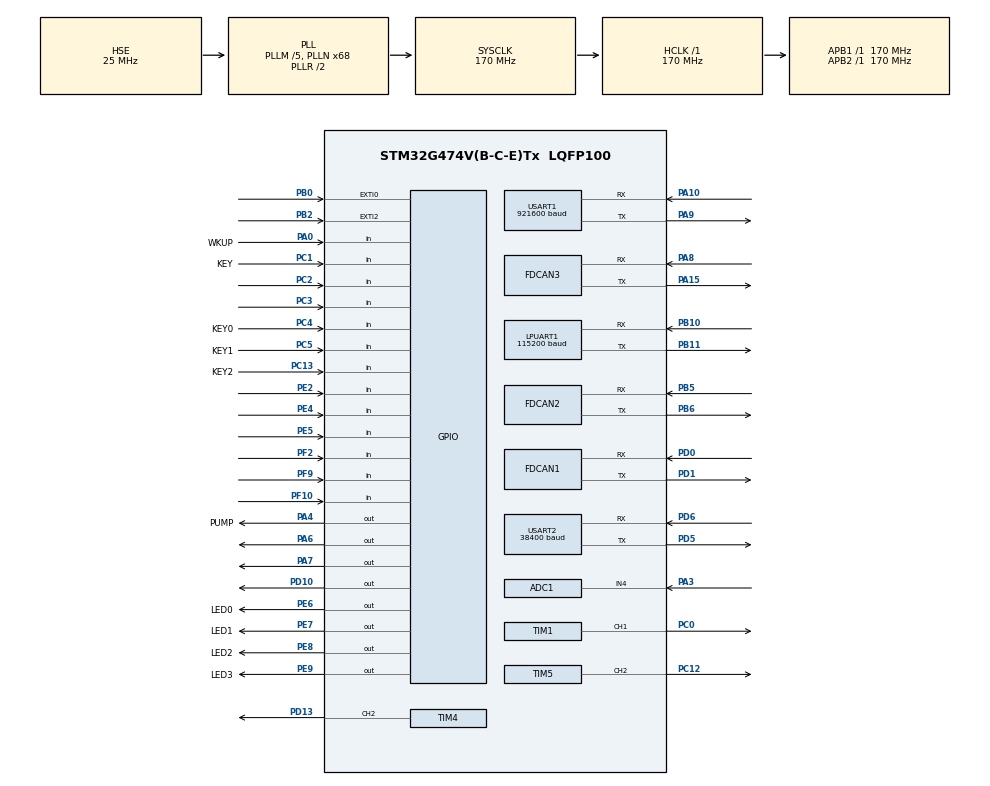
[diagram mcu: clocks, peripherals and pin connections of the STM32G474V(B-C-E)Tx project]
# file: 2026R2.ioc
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ADC1.Channel-1\#ChannelRegularConversion=ADC_CHANNEL_4
ADC1.ContinuousConvMode=ENABLE
ADC1.NbrOfConversionFlag=1
ADC1.OffsetNumber-1\#ChannelRegularConversion=ADC_OFFSET_NONE
ADC1.Overrun=ADC_OVR_DATA_OVERWRITTEN
ADC1.OversamplingMode=ENABLE
ADC1.Rank-1\#ChannelRegularConversion=1
ADC1.Ratio=ADC_OVERSAMPLING_RATIO_16
ADC1.RightBitShift=ADC_RIGHTBITSHIFT_4
ADC1.SamplingTime-1\#ChannelRegularConversion=ADC_SAMPLETIME_24CYCLES_5
ADC1.master=1
Dma.LPUART1_RX.2.Direction=DMA_PERIPH_TO_MEMORY
Dma.LPUART1_RX.2.EventEnable=DISABLE
Dma.LPUART1_RX.2.Instance=DMA1_Channel3
Dma.LPUART1_RX.2.MemDataAlignment=DMA_MDATAALIGN_BYTE
Dma.LPUART1_RX.2.MemInc=DMA_MINC_ENABLE
Dma.LPUART1_RX.2.Mode=DMA_NORMAL
Dma.LPUART1_RX.2.PeriphDataAlignment=DMA_PDATAALIGN_BYTE
Dma.LPUART1_RX.2.PeriphInc=DMA_PINC_DISABLE
Dma.LPUART1_RX.2.Polarity=HAL_DMAMUX_REQ_GEN_RISING
Dma.LPUART1_RX.2.Priority=DMA_PRIORITY_LOW
Dma.LPUART1_RX.2.RequestNumber=1
Dma.LPUART1_RX.2.SignalID=NONE
Dma.LPUART1_RX.2.SyncEnable=DISABLE
Dma.LPUART1_RX.2.SyncPolarity=HAL_DMAMUX_SYNC_NO_EVENT
Dma.LPUART1_RX.2.SyncRequestNumber=1
Dma.LPUART1_RX.2.SyncSignalID=NONE
Dma.LPUART1_TX.3.Direction=DMA_MEMORY_TO_PERIPH
Dma.LPUART1_TX.3.EventEnable=DISABLE
Dma.LPUART1_TX.3.Instance=DMA1_Channel4
Dma.LPUART1_TX.3.MemDataAlignment=DMA_MDATAALIGN_BYTE
Dma.LPUART1_TX.3.MemInc=DMA_MINC_ENABLE
Dma.LPUART1_TX.3.Mode=DMA_NORMAL
Dma.LPUART1_TX.3.PeriphDataAlignment=DMA_PDATAALIGN_BYTE
Dma.LPUART1_TX.3.PeriphInc=DMA_PINC_DISABLE
Dma.LPUART1_TX.3.Polarity=HAL_DMAMUX_REQ_GEN_RISING
Dma.LPUART1_TX.3.Priority=DMA_PRIORITY_LOW
Dma.LPUART1_TX.3.RequestNumber=1
Dma.LPUART1_TX.3.SignalID=NONE
Dma.LPUART1_TX.3.SyncEnable=DISABLE
Dma.LPUART1_TX.3.SyncPolarity=HAL_DMAMUX_SYNC_NO_EVENT
Dma.LPUART1_TX.3.SyncRequestNumber=1
Dma.LPUART1_TX.3.SyncSignalID=NONE
Dma.Request0=USART1_RX
Dma.Request1=USART1_TX
Dma.Request2=LPUART1_RX
Dma.Request3=LPUART1_TX
Dma.Request4=USART2_RX
Dma.Request5=USART2_TX
Dma.Request6=TIM5_CH2
Dma.Request7=TIM1_CH1
Dma.TIM1_CH1.7.Direction=DMA_MEMORY_TO_PERIPH
Dma.TIM1_CH1.7.EventEnable=DISABLE
Dma.TIM1_CH1.7.Instance=DMA2_Channel2
Dma.TIM1_CH1.7.MemDataAlignment=DMA_MDATAALIGN_HALFWORD
Dma.TIM1_CH1.7.MemInc=DMA_MINC_ENABLE
Dma.TIM1_CH1.7.Mode=DMA_NORMAL
Dma.TIM1_CH1.7.PeriphDataAlignment=DMA_PDATAALIGN_HALFWORD
Dma.TIM1_CH1.7.PeriphInc=DMA_PINC_DISABLE
Dma.TIM1_CH1.7.Polarity=HAL_DMAMUX_REQ_GEN_RISING
Dma.TIM1_CH1.7.Priority=DMA_PRIORITY_LOW
Dma.TIM1_CH1.7.RequestNumber=1
Dma.TIM1_CH1.7.SignalID=NONE
Dma.TIM1_CH1.7.SyncEnable=DISABLE
Dma.TIM1_CH1.7.SyncPolarity=HAL_DMAMUX_SYNC_NO_EVENT
Dma.TIM1_CH1.7.SyncRequestNumber=1
Dma.TIM1_CH1.7.SyncSignalID=NONE
Dma.TIM5_CH2.6.Direction=DMA_MEMORY_TO_PERIPH
Dma.TIM5_CH2.6.EventEnable=DISABLE
Dma.TIM5_CH2.6.Instance=DMA2_Channel1
Dma.TIM5_CH2.6.MemDataAlignment=DMA_MDATAALIGN_HALFWORD
Dma.TIM5_CH2.6.MemInc=DMA_MINC_ENABLE
Dma.TIM5_CH2.6.Mode=DMA_NORMAL
Dma.TIM5_CH2.6.PeriphDataAlignment=DMA_PDATAALIGN_HALFWORD
Dma.TIM5_CH2.6.PeriphInc=DMA_PINC_DISABLE
Dma.TIM5_CH2.6.Polarity=HAL_DMAMUX_REQ_GEN_RISING
Dma.TIM5_CH2.6.Priority=DMA_PRIORITY_MEDIUM
Dma.TIM5_CH2.6.RequestNumber=1
Dma.TIM5_CH2.6.SignalID=NONE
Dma.TIM5_CH2.6.SyncEnable=DISABLE
Dma.TIM5_CH2.6.SyncPolarity=HAL_DMAMUX_SYNC_NO_EVENT
Dma.TIM5_CH2.6.SyncRequestNumber=1
Dma.TIM5_CH2.6.SyncSignalID=NONE
Dma.USART1_RX.0.Direction=DMA_PERIPH_TO_MEMORY
Dma.USART1_RX.0.EventEnable=DISABLE
Dma.USART1_RX.0.Instance=DMA1_Channel1
Dma.USART1_RX.0.MemDataAlignment=DMA_MDATAALIGN_BYTE
Dma.USART1_RX.0.MemInc=DMA_MINC_ENABLE
Dma.USART1_RX.0.Mode=DMA_NORMAL
Dma.USART1_RX.0.PeriphDataAlignment=DMA_PDATAALIGN_BYTE
Dma.USART1_RX.0.PeriphInc=DMA_PINC_DISABLE
Dma.USART1_RX.0.Polarity=HAL_DMAMUX_REQ_GEN_RISING
Dma.USART1_RX.0.Priority=DMA_PRIORITY_MEDIUM
Dma.USART1_RX.0.RequestNumber=1
Dma.USART1_RX.0.SignalID=NONE
Dma.USART1_RX.0.SyncEnable=DISABLE
Dma.USART1_RX.0.SyncPolarity=HAL_DMAMUX_SYNC_NO_EVENT
Dma.USART1_RX.0.SyncRequestNumber=1
Dma.USART1_RX.0.SyncSignalID=NONE
Dma.USART1_TX.1.Direction=DMA_MEMORY_TO_PERIPH
Dma.USART1_TX.1.EventEnable=DISABLE
Dma.USART1_TX.1.Instance=DMA1_Channel2
Dma.USART1_TX.1.MemDataAlignment=DMA_MDATAALIGN_BYTE
Dma.USART1_TX.1.MemInc=DMA_MINC_ENABLE
Dma.USART1_TX.1.Mode=DMA_NORMAL
Dma.USART1_TX.1.PeriphDataAlignment=DMA_PDATAALIGN_BYTE
Dma.USART1_TX.1.PeriphInc=DMA_PINC_DISABLE
Dma.USART1_TX.1.Polarity=HAL_DMAMUX_REQ_GEN_RISING
Dma.USART1_TX.1.Priority=DMA_PRIORITY_MEDIUM
Dma.USART1_TX.1.RequestNumber=1
Dma.USART1_TX.1.SignalID=NONE
Dma.USART1_TX.1.SyncEnable=DISABLE
Dma.USART1_TX.1.SyncPolarity=HAL_DMAMUX_SYNC_NO_EVENT
Dma.USART1_TX.1.SyncRequestNumber=1
Dma.USART1_TX.1.SyncSignalID=NONE
Dma.USART2_RX.4.Direction=DMA_PERIPH_TO_MEMORY
Dma.USART2_RX.4.EventEnable=DISABLE
Dma.USART2_RX.4.Instance=DMA1_Channel7
Dma.USART2_RX.4.MemDataAlignment=DMA_MDATAALIGN_BYTE
Dma.USART2_RX.4.MemInc=DMA_MINC_ENABLE
Dma.USART2_RX.4.Mode=DMA_NORMAL
Dma.USART2_RX.4.PeriphDataAlignment=DMA_PDATAALIGN_BYTE
Dma.USART2_RX.4.PeriphInc=DMA_PINC_DISABLE
Dma.USART2_RX.4.Polarity=HAL_DMAMUX_REQ_GEN_RISING
Dma.USART2_RX.4.Priority=DMA_PRIORITY_LOW
Dma.USART2_RX.4.RequestNumber=1
Dma.USART2_RX.4.SignalID=NONE
Dma.USART2_RX.4.SyncEnable=DISABLE
Dma.USART2_RX.4.SyncPolarity=HAL_DMAMUX_SYNC_NO_EVENT
Dma.USART2_RX.4.SyncRequestNumber=1
Dma.USART2_RX.4.SyncSignalID=NONE
Dma.USART2_TX.5.Direction=DMA_MEMORY_TO_PERIPH
Dma.USART2_TX.5.EventEnable=DISABLE
Dma.USART2_TX.5.Instance=DMA1_Channel8
Dma.USART2_TX.5.MemDataAlignment=DMA_MDATAALIGN_BYTE
Dma.USART2_TX.5.MemInc=DMA_MINC_ENABLE
Dma.USART2_TX.5.Mode=DMA_NORMAL
Dma.USART2_TX.5.PeriphDataAlignment=DMA_PDATAALIGN_BYTE
Dma.USART2_TX.5.PeriphInc=DMA_PINC_DISABLE
Dma.USART2_TX.5.Polarity=HAL_DMAMUX_REQ_GEN_RISING
Dma.USART2_TX.5.Priority=DMA_PRIORITY_LOW
Dma.USART2_TX.5.RequestNumber=1
Dma.USART2_TX.5.SignalID=NONE
Dma.USART2_TX.5.SyncEnable=DISABLE
Dma.USART2_TX.5.SyncPolarity=HAL_DMAMUX_SYNC_NO_EVENT
Dma.USART2_TX.5.SyncRequestNumber=1
Dma.USART2_TX.5.SyncSignalID=NONE
FDCAN1.AutoRetransmission=ENABLE
FDCAN1.CalculateBaudRateNominal=999999
FDCAN1.CalculateTimeBitNominal=1000
FDCAN1.CalculateTimeQuantumNominal=58.82352941176471
FDCAN1.ClockDivider=FDCAN_CLOCK_DIV1
FDCAN1.ExtFiltersNbr=2
FDCAN1.NominalPrescaler=10
FDCAN1.NominalSyncJumpWidth=4
FDCAN1.NominalTimeSeg1=10
FDCAN1.NominalTimeSeg2=6
FDCAN1.ProtocolException=ENABLE
FDCAN1.StdFiltersNbr=2
FDCAN2.AutoRetransmission=ENABLE
FDCAN2.CalculateBaudRateNominal=999999
FDCAN2.CalculateTimeBitNominal=1000
FDCAN2.CalculateTimeQuantumNominal=58.82352941176471
FDCAN2.ExtFiltersNbr=2
FDCAN2.NominalPrescaler=10
FDCAN2.NominalSyncJumpWidth=4
FDCAN2.NominalTimeSeg1=10
FDCAN2.NominalTimeSeg2=6
FDCAN2.ProtocolException=ENABLE
FDCAN2.StdFiltersNbr=2
FDCAN3.AutoRetransmission=ENABLE
FDCAN3.CalculateBaudRateNominal=999999
FDCAN3.CalculateTimeBitNominal=1000
FDCAN3.CalculateTimeQuantumNominal=58.82352941176471
FDCAN3.ExtFiltersNbr=2
FDCAN3.NominalPrescaler=10
FDCAN3.NominalSyncJumpWidth=4
FDCAN3.NominalTimeSeg1=10
FDCAN3.NominalTimeSeg2=6
FDCAN3.ProtocolException=ENABLE
FDCAN3.StdFiltersNbr=2
LPUART1.BaudRate=115200
LPUART1.ClockPrescaler=UART_PRESCALER_DIV1
Mcu.Family=STM32G4
Mcu.Name=STM32G474V(B-C-E)Tx
Mcu.Package=LQFP100
NVIC.DMA1_Channel1_IRQn=true\:6\:0\:true\:false\:true\:false\:true\:true
NVIC.DMA1_Channel2_IRQn=true\:6\:0\:true\:false\:true\:false\:true\:true
NVIC.DMA1_Channel3_IRQn=true\:6\:0\:true\:false\:true\:false\:true\:true
NVIC.DMA1_Channel4_IRQn=true\:6\:0\:true\:false\:true\:false\:true\:true
NVIC.DMA1_Channel7_IRQn=true\:6\:0\:true\:false\:true\:false\:true\:true
NVIC.DMA1_Channel8_IRQn=true\:6\:0\:true\:false\:true\:false\:true\:true
NVIC.DMA2_Channel1_IRQn=true\:0\:0\:false\:false\:true\:false\:true\:true
NVIC.DMA2_Channel2_IRQn=true\:0\:0\:false\:false\:true\:false\:true\:true
NVIC.EXTI0_IRQn=true\:0\:0\:false\:false\:true\:true\:true\:true
NVIC.EXTI2_IRQn=true\:0\:0\:false\:false\:true\:true\:true\:true
NVIC.FDCAN1_IT0_IRQn=true\:5\:0\:true\:false\:true\:true\:true\:true
NVIC.FDCAN1_IT1_IRQn=true\:5\:0\:true\:false\:true\:true\:true\:true
NVIC.FDCAN2_IT0_IRQn=true\:5\:0\:true\:false\:true\:true\:true\:true
NVIC.FDCAN2_IT1_IRQn=true\:5\:0\:true\:false\:true\:true\:true\:true
NVIC.FDCAN3_IT0_IRQn=true\:5\:0\:true\:false\:true\:true\:true\:true
NVIC.FDCAN3_IT1_IRQn=true\:5\:0\:true\:false\:true\:true\:true\:true
NVIC.LPUART1_IRQn=true\:6\:0\:true\:false\:true\:true\:true\:true
NVIC.PriorityGroup=NVIC_PRIORITYGROUP_4
NVIC.USART1_IRQn=true\:6\:0\:true\:false\:true\:true\:true\:true
NVIC.USART2_IRQn=true\:6\:0\:true\:false\:true\:true\:true\:true
PA0.GPIO_Label=WKUP
PA0.GPIO_PuPd=GPIO_PULLDOWN
PA0.Signal=GPIO_Input
PA10.GPIO_PuPd=GPIO_PULLUP
PA10.GPIO_Speed=GPIO_SPEED_FREQ_HIGH
PA10.Mode=Asynchronous
PA10.Signal=USART1_RX
PA13.Mode=Trace_Asynchronous_SW
PA13.Signal=SYS_JTMS-SWDIO
PA14.Mode=Trace_Asynchronous_SW
PA14.Signal=SYS_JTCK-SWCLK
PA15.Mode=FDCAN_Activate
PA15.Signal=FDCAN3_TX
PA3.GPIO_Pd=GPIO_NOPULL
PA3.Mode=IN4-Single-Ended
PA3.Signal=ADC1_IN4
PA4.GPIO_Label=PUMP
PA4.Signal=GPIO_Output
PA6.GPIO_PuPd=GPIO_PULLDOWN
PA6.Signal=GPIO_Output
PA7.GPIO_PuPd=GPIO_PULLDOWN
PA7.Signal=GPIO_Output
PA8.Mode=FDCAN_Activate
PA8.Signal=FDCAN3_RX
PA9.GPIO_PuPd=GPIO_PULLUP
PA9.GPIO_Speed=GPIO_SPEED_FREQ_HIGH
PA9.Mode=Asynchronous
PA9.Signal=USART1_TX
PB0.GPIO_ModeDefaultEXTI=GPIO_MODE_IT_FALLING
PB0.GPIO_PuPd=GPIO_PULLUP
PB0.Signal=GPXTI0
PB10.GPIO_PuPd=GPIO_PULLUP
PB10.GPIO_Speed=GPIO_SPEED_FREQ_HIGH
PB10.Mode=Asynchronous
PB10.Signal=LPUART1_RX
PB11.GPIO_PuPd=GPIO_PULLUP
PB11.GPIO_Speed=GPIO_SPEED_FREQ_HIGH
PB11.Mode=Asynchronous
PB11.Signal=LPUART1_TX
PB2.GPIO_ModeDefaultEXTI=GPIO_MODE_IT_FALLING
PB2.GPIO_PuPd=GPIO_PULLUP
PB2.Signal=GPXTI2
PB3.Mode=Trace_Asynchronous_SW
PB3.Signal=SYS_JTDO-SWO
PB5.Mode=FDCAN_Activate
PB5.Signal=FDCAN2_RX
PB6.Mode=FDCAN_Activate
PB6.Signal=FDCAN2_TX
PC0.Signal=S_TIM1_CH1
PC1.GPIO_Label=KEY
PC1.GPIO_PuPd=GPIO_PULLUP
PC1.Signal=GPIO_Input
PC12.Signal=S_TIM5_CH2
PC13.GPIO_Label=KEY2
PC13.GPIO_PuPd=GPIO_PULLUP
PC13.Signal=GPIO_Input
PC14-OSC32_IN.Mode=LSE-External-Oscillator
PC14-OSC32_IN.Signal=RCC_OSC32_IN
PC15-OSC32_OUT.Mode=LSE-External-Oscillator
PC15-OSC32_OUT.Signal=RCC_OSC32_OUT
PC2.GPIO_PuPd=GPIO_PULLUP
PC2.Signal=GPIO_Input
PC3.GPIO_PuPd=GPIO_PULLUP
PC3.Signal=GPIO_Input
PC4.GPIO_Label=KEY0
PC4.GPIO_PuPd=GPIO_PULLUP
PC4.Signal=GPIO_Input
PC5.GPIO_Label=KEY1
PC5.GPIO_PuPd=GPIO_PULLUP
PC5.Signal=GPIO_Input
PD0.Mode=FDCAN_Activate
PD0.Signal=FDCAN1_RX
PD1.Mode=FDCAN_Activate
PD1.Signal=FDCAN1_TX
PD10.Signal=GPIO_Output
PD13.Signal=S_TIM4_CH2
PD5.GPIO_PuPd=GPIO_PULLUP
PD5.GPIO_Speed=GPIO_SPEED_FREQ_HIGH
PD5.Mode=Asynchronous
PD5.Signal=USART2_TX
PD6.GPIO_PuPd=GPIO_PULLUP
PD6.GPIO_Speed=GPIO_SPEED_FREQ_HIGH
PD6.Mode=Asynchronous
PD6.Signal=USART2_RX
PE2.Signal=GPIO_Input
PE4.Signal=GPIO_Input
PE5.Signal=GPIO_Input
PE6.GPIO_Label=LED0
PE6.GPIO_PuPd=GPIO_PULLUP
PE6.GPIO_Speed=GPIO_SPEED_FREQ_HIGH
PE6.Signal=GPIO_Output
PE7.GPIO_Label=LED1
PE7.GPIO_PuPd=GPIO_PULLUP
PE7.GPIO_Speed=GPIO_SPEED_FREQ_HIGH
PE7.PinState=GPIO_PIN_SET
PE7.Signal=GPIO_Output
PE8.GPIO_Label=LED2
PE8.GPIO_PuPd=GPIO_PULLUP
PE8.GPIO_Speed=GPIO_SPEED_FREQ_HIGH
PE8.Signal=GPIO_Output
PE9.GPIO_Label=LED3
PE9.GPIO_PuPd=GPIO_PULLUP
PE9.GPIO_Speed=GPIO_SPEED_FREQ_HIGH
PE9.PinState=GPIO_PIN_SET
PE9.Signal=GPIO_Output
PF0-OSC_IN.Mode=HSE-External-Oscillator
PF0-OSC_IN.Signal=RCC_OSC_IN
PF1-OSC_OUT.Mode=HSE-External-Oscillator
PF1-OSC_OUT.Signal=RCC_OSC_OUT
PF10.Signal=GPIO_Input
PF2.Signal=GPIO_Input
PF9.Signal=GPIO_Input
ProjectManager.HeapSize=0x2000
ProjectManager.StackSize=0x2000
ProjectManager.TargetToolchain=Makefile
RCC.ADC12Freq_Value=170000000
RCC.ADC345Freq_Value=170000000
RCC.AHBFreq_Value=170000000
RCC.APB1Freq_Value=170000000
RCC.APB1TimFreq_Value=170000000
RCC.APB2Freq_Value=170000000
RCC.APB2TimFreq_Value=170000000
RCC.CortexFreq_Value=170000000
RCC.EXTERNAL_CLOCK_VALUE=12288000
RCC.HCLKFreq_Value=170000000
RCC.HSE_VALUE=25000000
RCC.HSI48_VALUE=48000000
RCC.HSI_VALUE=16000000
RCC.PLLM=RCC_PLLM_DIV5
RCC.PLLN=68
RCC.PLLSourceVirtual=RCC_PLLSOURCE_HSE
RCC.SYSCLKFreq_VALUE=170000000
RCC.SYSCLKSource=RCC_SYSCLKSOURCE_PLLCLK
RCC.USBFreq_Value=170000000
RCC.VCOOutputFreq_Value=340000000
SH.S_TIM1_CH1.0=TIM1_CH1,PWM Generation1 CH1
SH.S_TIM4_CH2.0=TIM4_CH2,PWM Generation2 CH2
SH.S_TIM5_CH2.0=TIM5_CH2,PWM Generation2 CH2
SYS.VoltageScaling=SYSCFG_VREFBUF_VOLTAGE_SCALE1
TIM1.AutoReloadPreload=TIM_AUTORELOAD_PRELOAD_ENABLE
TIM1.Channel-PWM\ Generation1\ CH1=TIM_CHANNEL_1
TIM1.PeriodNoDither=211
TIM1.Prescaler=0
TIM3.AutoReloadPreload=TIM_AUTORELOAD_PRELOAD_ENABLE
TIM3.PeriodNoDither=19999
TIM3.Prescaler=169
TIM4.AutoReloadPreload=TIM_AUTORELOAD_PRELOAD_ENABLE
TIM4.Channel-PWM\ Generation2\ CH2=TIM_CHANNEL_2
TIM4.PeriodNoDither=19999
TIM4.Prescaler=169
TIM5.AutoReloadPreload=TIM_AUTORELOAD_PRELOAD_ENABLE
TIM5.Channel-PWM\ Generation2\ CH2=TIM_CHANNEL_2
TIM5.PeriodNoDither=211
USART1.BaudRate=921600
USART1.OverrunDisableParam=ADVFEATURE_OVERRUN_ENABLE
USART1.VirtualMode-Asynchronous=VM_ASYNC
USART2.BaudRate=38400
USART2.VirtualMode-Asynchronous=VM_ASYNC
VP_SYS_VS_DBSignals.Mode=DisableDeadBatterySignals
VP_TIM1_VS_ClockSourceINT.Mode=Internal
VP_TIM3_VS_ClockSourceINT.Mode=Internal
VP_TIM5_VS_ClockSourceINT.Mode=Internal
VREF+.Mode=InternalMode
VREF+.Signal=VREFBUF_OUT
board=custom

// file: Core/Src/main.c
/* USER CODE BEGIN Header */
/**
  ******************************************************************************
  * @file           : main.c
  * @brief          : Main program body
  ******************************************************************************
  * @attention
  *
  * Copyright (c) 2026 STMicroelectronics.
  * All rights reserved.
  *
  * This software is licensed under terms that can be found in the LICENSE file
  * in the root directory of this software component.
  * If no LICENSE file comes with this software, it is provided AS-IS.
  *
  ******************************************************************************
  */
/* USER CODE END Header */
#include "main.h"
#include "adc.h"
#include "dma.h"
#include "fdcan.h"
#include "usart.h"
#include "tim.h"
#include "gpio.h"

/* USER CODE BEGIN Includes */
#include <bsp.h>
/* USER CODE END Includes */

void SystemClock_Config(void);
/* USER CODE BEGIN PFP */
extern void freertos_start(void);
/* USER CODE END PFP */

int main(void)
{

  /* MCU Configuration--------------------------------------------------------*/

  /* Reset of all peripherals, Initializes the Flash interface and the Systick. */
  HAL_Init();

  /* Configure the system clock */
  SystemClock_Config();

  /* USER CODE BEGIN SysInit */
  delay_init(170);
  /* USER CODE END SysInit */

  /* Initialize all configured peripherals */
  MX_GPIO_Init();
  MX_DMA_Init();
  MX_USART1_UART_Init();
  MX_FDCAN1_Init();
  MX_FDCAN2_Init();
  MX_FDCAN3_Init();
  MX_LPUART1_UART_Init();
  MX_USART2_UART_Init();
  MX_ADC1_Init();
  MX_TIM5_Init();
  MX_TIM3_Init();
  MX_TIM4_Init();
  MX_TIM1_Init();
  /* USER CODE BEGIN 2 */
  bsp_init();
  freertos_start();
  /* USER CODE END 2 */

  /* Infinite loop */
  /* USER CODE BEGIN WHILE */
#if 0
  while (1)
  {
    /* USER CODE END WHILE */

    /* USER CODE BEGIN 3 */
  }
#endif /* 0 */
  /* USER CODE END 3 */
}

void SystemClock_Config(void)
{
  RCC_OscInitTypeDef RCC_OscInitStruct = {0};
  RCC_ClkInitTypeDef RCC_ClkInitStruct = {0};

  /** Configure the main internal regulator output voltage
  */
  HAL_PWREx_ControlVoltageScaling(PWR_REGULATOR_VOLTAGE_SCALE1_BOOST);

  /** Initializes the RCC Oscillators according to the specified parameters
  * in the RCC_OscInitTypeDef structure.
  */
  RCC_OscInitStruct.OscillatorType = RCC_OSCILLATORTYPE_HSE;
  RCC_OscInitStruct.HSEState = RCC_HSE_ON;
  RCC_OscInitStruct.PLL.PLLState = RCC_PLL_ON;
  RCC_OscInitStruct.PLL.PLLSource = RCC_PLLSOURCE_HSE;
  RCC_OscInitStruct.PLL.PLLM = RCC_PLLM_DIV5;
  RCC_OscInitStruct.PLL.PLLN = 68;
  RCC_OscInitStruct.PLL.PLLP = RCC_PLLP_DIV2;
  RCC_OscInitStruct.PLL.PLLQ = RCC_PLLQ_DIV2;
  RCC_OscInitStruct.PLL.PLLR = RCC_PLLR_DIV2;
  if (HAL_RCC_OscConfig(&RCC_OscInitStruct) != HAL_OK)
  {
    Error_Handler();
  }

  /** Initializes the CPU, AHB and APB buses clocks
  */
  RCC_ClkInitStruct.ClockType = RCC_CLOCKTYPE_HCLK|RCC_CLOCKTYPE_SYSCLK
                              |RCC_CLOCKTYPE_PCLK1|RCC_CLOCKTYPE_PCLK2;
  RCC_ClkInitStruct.SYSCLKSource = RCC_SYSCLKSOURCE_PLLCLK;
  RCC_ClkInitStruct.AHBCLKDivider = RCC_SYSCLK_DIV1;
  RCC_ClkInitStruct.APB1CLKDivider = RCC_HCLK_DIV1;
  RCC_ClkInitStruct.APB2CLKDivider = RCC_HCLK_DIV1;

  if (HAL_RCC_ClockConfig(&RCC_ClkInitStruct, FLASH_LATENCY_4) != HAL_OK)
  {
    Error_Handler();
  }
}

void Error_Handler(void)
{
  __disable_irq();
  while (1)
  {
  }
}
